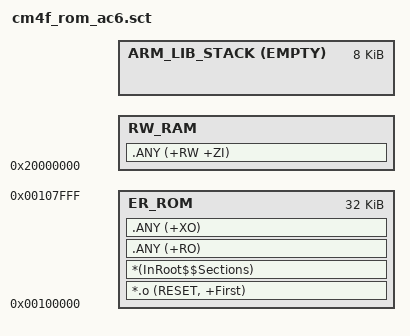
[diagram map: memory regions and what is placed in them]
#! armclang -E --target=arm-arm-none-eabi -mcpu=cortex-m33 -xc
; command above MUST be in first line (no comment above!)

/* ----------------------------------------------------------------------------
 * All rights reserved.
 *
 * This software is licensed under terms that can be found in the LICENSE file
 * in the root directory of this software component.
 * If no LICENSE file comes with this software, it is provided AS-IS.
 * -------------------------------------------------------------------------- */

/**
 * @defgroup DOC DOC
 * @ingroup  DOCUMENT
 * @brief    linker script for flash version
 * @details
 *
 * @version
 * Version 1.0
 *  - Initial release
 *
 * @{
 */

/*
 *--------- <<< Use Configuration Wizard in Context Menu >>> -------------------
 */
/*--------------------- ROM Configuration --------------------------------------
; <h> ROM Configuration
;   <o0> ROM Base Address <0x0-0xFFFFFFFF:8>
;   <o1> ROM Size (in Bytes) <0x0-0xFFFFFFFF:8>
; </h>
------------------------------------------------------------------------------*/
#define __ROM_BASE      0x00100000
#define __ROM_SIZE      0x00008000

/*--------------------- Embedded RAM Configuration ---------------------------
; <h> RAM Configuration
;   <o0> RAM Base Address    <0x0-0xFFFFFFFF:8>
;   <o1> RAM Size (in Bytes) <0x0-0xFFFFFFFF:8>
; </h>
 *----------------------------------------------------------------------------*/
#define __RAM_BASE      0x20000000
#define __RAM_SIZE      0x00020000

/*---------------------- Stack / Heap Configuration ----------------------------
  <h> Stack / Heap Configuration
    <o0> Stack Size (in Bytes) <0x0-0xFFFFFFFF:8>
    <o1> Heap Size (in Bytes) <0x0-0xFFFFFFFF:8>
  </h>
------------------------------------------------------------------------------*/
#define __STACK_SIZE    0x00002000
#define __HEAP_SIZE     0x00000000

/*
;------------- <<< end of configuration section >>> ---------------------------
*/

/*----------------------------------------------------------------------------
  Scatter File Definitions definition
 *----------------------------------------------------------------------------*/
#define __RO_BASE       __ROM_BASE
#define __RO_SIZE       __ROM_SIZE

#define __RW_BASE       __RAM_BASE
#define __RW_SIZE      (__RAM_SIZE - __STACK_SIZE - __HEAP_SIZE)


LR_ROM __RO_BASE __RO_SIZE  {                       ; load region size_region
  ER_ROM __RO_BASE __RO_SIZE  {                     ; load address = execution address
   *.o (RESET, +First)
   *(InRoot$$Sections)
   .ANY (+RO)
   .ANY (+XO)
  }

  RW_RAM __RW_BASE ALIGN 4 {   ; RW data
   .ANY (+RW +ZI)
  }

#if __HEAP_SIZE > 0
  ARM_LIB_HEAP  +0 ALIGN 8 EMPTY  __HEAP_SIZE  {   ; Reserve empty region for heap
  }
#endif

  ARM_LIB_STACK +0 ALIGN 8 EMPTY __STACK_SIZE {   ; Reserve empty region for stack
  }
}
